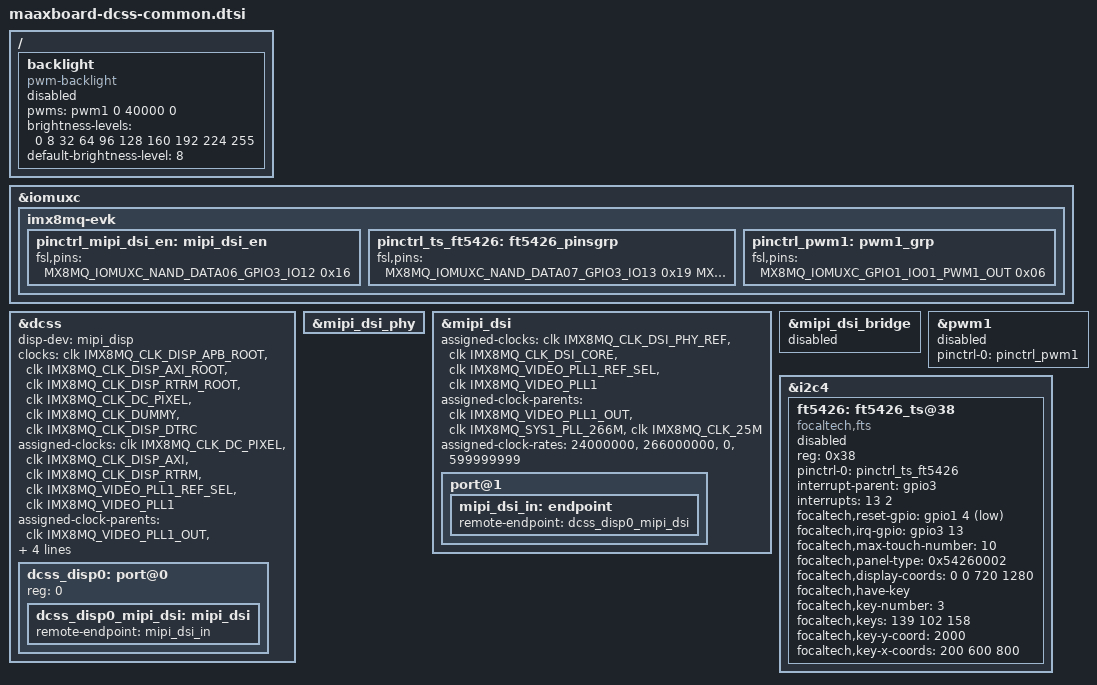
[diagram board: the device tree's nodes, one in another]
/*
 * Copyright 2019 EMBEST
 *
 * This program is free software; you can redistribute it and/or
 * modify it under the terms of the GNU General Public License
 * as published by the Free Software Foundation; either version 2
 * of the License, or (at your option) any later version.
 *
 * This program is distributed in the hope that it will be useful,
 * but WITHOUT ANY WARRANTY; without even the implied warranty of
 * MERCHANTABILITY or FITNESS FOR A PARTICULAR PURPOSE.  See the
 * GNU General Public License for more details.
 */

/ {
	backlight: backlight {
			compatible = "pwm-backlight";
			pwms = <&pwm1 0 40000 0>;
			brightness-levels = <0 8 32 64 96 128 160 192 224 255>;
			default-brightness-level = <8>;
			status = "disabled";
	};
};

&iomuxc {
	imx8mq-evk {
		pinctrl_mipi_dsi_en: mipi_dsi_en {
			fsl,pins = <
				MX8MQ_IOMUXC_NAND_DATA06_GPIO3_IO12		0x16  /* DSI_EN */
			>;
		};

		pinctrl_ts_ft5426: ft5426_pinsgrp {
			fsl,pins = <
				MX8MQ_IOMUXC_NAND_DATA07_GPIO3_IO13		0x19  /* DSI_TS_nINT */
				MX8MQ_IOMUXC_GPIO1_IO04_GPIO1_IO4		0x19  /* DSI_TS_RST  */
			>;
		};

		pinctrl_pwm1: pwm1_grp {
			fsl,pins = <
				MX8MQ_IOMUXC_GPIO1_IO01_PWM1_OUT		0x06
			>;
		};
	};
};

&dcss {
	status = "okay";
	disp-dev = "mipi_disp";

	clocks = <&clk IMX8MQ_CLK_DISP_APB_ROOT>,
		 <&clk IMX8MQ_CLK_DISP_AXI_ROOT>,
		 <&clk IMX8MQ_CLK_DISP_RTRM_ROOT>,
		 <&clk IMX8MQ_CLK_DC_PIXEL>,
		 <&clk IMX8MQ_CLK_DUMMY>,
		 <&clk IMX8MQ_CLK_DISP_DTRC>;
	clock-names = "apb", "axi", "rtrm", "pix_div", "pix_out", "dtrc";

	assigned-clocks = <&clk IMX8MQ_CLK_DC_PIXEL>,
			  <&clk IMX8MQ_CLK_DISP_AXI>,
			  <&clk IMX8MQ_CLK_DISP_RTRM>,
			  <&clk IMX8MQ_VIDEO_PLL1_REF_SEL>,
			  <&clk IMX8MQ_VIDEO_PLL1>;
	assigned-clock-parents = <&clk IMX8MQ_VIDEO_PLL1_OUT>,
				 <&clk IMX8MQ_SYS1_PLL_800M>,
				 <&clk IMX8MQ_SYS1_PLL_800M>,
				 <&clk IMX8MQ_CLK_25M>;
	assigned-clock-rates = <600000000>,
			       <800000000>,
			       <0>,
			       <400000000>,
			       <599999999>;

	dcss_disp0: port@0 {
		reg = <0>;

		dcss_disp0_mipi_dsi: mipi_dsi {
			remote-endpoint = <&mipi_dsi_in>;
		};
	};
};

&mipi_dsi_phy {
	status = "okay";
};

&mipi_dsi {
	status = "okay";
	assigned-clocks = <&clk IMX8MQ_CLK_DSI_PHY_REF>,
			  <&clk IMX8MQ_CLK_DSI_CORE>,
			  <&clk IMX8MQ_VIDEO_PLL1_REF_SEL>,
			  <&clk IMX8MQ_VIDEO_PLL1>;
	assigned-clock-parents = <&clk IMX8MQ_VIDEO_PLL1_OUT>,
				 <&clk IMX8MQ_SYS1_PLL_266M>,
				 <&clk IMX8MQ_CLK_25M>;
	assigned-clock-rates = <24000000>,
			       <266000000>,
			       <0>,
			       <599999999>;

	port@1 {
		mipi_dsi_in: endpoint {
			remote-endpoint = <&dcss_disp0_mipi_dsi>;
		};
	};

};

&mipi_dsi_bridge {
	status = "disabled";
};

&pwm1 {
        pinctrl-names = "default";
        pinctrl-0 = <&pinctrl_pwm1>;
        status = "disabled";
};

&i2c4 {
	status = "okay";

	ft5426: ft5426_ts@38 {
		compatible = "focaltech,fts";
		reg = <0x38>;
		pinctrl-0 = <&pinctrl_ts_ft5426>;

		interrupt-parent = <&gpio3>;
		interrupts = <13 2>;
		focaltech,reset-gpio = <&gpio1 4 0x01>;
		focaltech,irq-gpio = <&gpio3 13 0x02>;
		focaltech,max-touch-number = <10>;
		focaltech,panel-type = <0x54260002>; /* _FT5426 */
		focaltech,display-coords =  <0 0 720 1280>;
		focaltech,have-key;
		focaltech,key-number = <3>;
		focaltech,keys = <139 102 158>;
		focaltech,key-y-coord = <2000>;
		focaltech,key-x-coords = <200 600 800>;
		status = "disabled";
	};
};

